# MKL28Z7 register map
Vendor: Freescale Semiconductor, Inc.; Series: Kinetis_L; File version: 1.6
CPU: CM0PLUS r0p0, little endian, no MPU, no FPU, VTOR, 2 interrupt priority bits
Registers are 32-bit, read-write, reset 0x0 unless marked. A register's access mark holds for its fields unless they carry their own. Offsets are from the block's base; [hi:lo] are bit positions; {n}, {i} and the like mark numbered series.

## USB0 — Universal Serial Bus, OTG Capable Controller
Base 0x40055000; register names take the prefix USB0_
0x00 PERID 8-bit ro reset 0x4 — Peripheral ID register
  [5:0] ID — Peripheral Identification
0x04 IDCOMP 8-bit ro reset 0xFB — Peripheral ID Complement register
  [5:0] NID — Ones' complement of PERID[ID] bits.
0x08 REV 8-bit ro reset 0x33 — Peripheral Revision register
  [7:0] REV — Revision
0x0C ADDINFO 8-bit ro reset 0x1 — Peripheral Additional Info register
  [0] IEHOST — This bit is set if host mode is enabled.
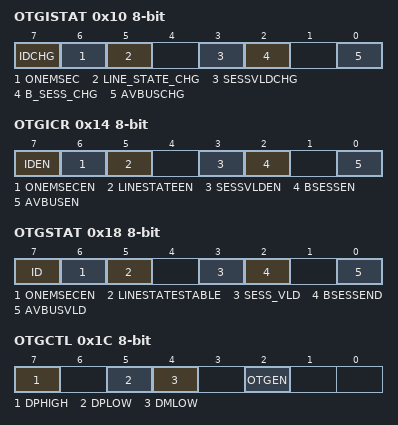
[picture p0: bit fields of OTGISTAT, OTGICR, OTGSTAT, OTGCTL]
0x10 OTGISTAT 8-bit — OTG Interrupt Status register
  [7] IDCHG — This bit is set when a change in the ID Signal from the USB connector is sensed.
  [6] ONEMSEC — This bit is set when the 1 millisecond timer expires
  [5] LINE_STATE_CHG — This interrupt is set when the USB line state (CTL[SE0] and CTL[JSTATE] bits) are stable without change for 1 millisecond, and the value of the line state is different from the last time when the line state was stable
  [3] SESSVLDCHG — This bit is set when a change in VBUS is detected indicating a session valid or a session no longer valid
  [2] B_SESS_CHG — This bit is set when a change in VBUS is detected on a B device.
  [0] AVBUSCHG — This bit is set when a change in VBUS is detected on an A device.
0x14 OTGICR 8-bit — OTG Interrupt Control register
  [7] IDEN — ID Interrupt Enable
    0=The ID interrupt is disabled; 1=The ID interrupt is enabled
  [6] ONEMSECEN — One Millisecond Interrupt Enable
    0=Diables the 1ms timer interrupt; 1=Enables the 1ms timer interrupt
  [5] LINESTATEEN — Line State Change Interrupt Enable
    0=Disables the LINE_STAT_CHG interrupt; 1=Enables the LINE_STAT_CHG interrupt
  [3] SESSVLDEN — Session Valid Interrupt Enable
    0=Disables the SESSVLDCHG interrupt; 1=Enables the SESSVLDCHG interrupt
  [2] BSESSEN — B Session END Interrupt Enable
    0=Disables the B_SESS_CHG interrupt; 1=Enables the B_SESS_CHG interrupt
  [0] AVBUSEN — A VBUS Valid Interrupt Enable
    0=Disables the AVBUSCHG interrupt; 1=Enables the AVBUSCHG interrupt
0x18 OTGSTAT 8-bit — OTG Status register
  [7] ID — Indicates the current state of the ID pin on the USB connector
    0=Indicates a Type A cable is plugged into the USB connector; 1=Indicates no cable is attached or a Type B cable is plugged into the USB connector
  [6] ONEMSECEN — This bit is reserved for the 1ms count, but it is not useful to software.
  [5] LINESTATESTABLE — Indicates that the internal signals that control the LINE_STATE_CHG field of OTGISTAT are stable for at least 1 ms
    0=The LINE_STAT_CHG bit is not yet stable; 1=The LINE_STAT_CHG bit has been debounced and is stable
  [3] SESS_VLD — Session Valid
    0=The VBUS voltage is below the B session valid threshold; 1=The VBUS voltage is above the B session valid threshold
  [2] BSESSEND — B Session End
    0=The VBUS voltage is above the B session end threshold; 1=The VBUS voltage is below the B session end threshold
  [0] AVBUSVLD — A VBUS Valid
    0=The VBUS voltage is below the A VBUS Valid threshold; 1=The VBUS voltage is above the A VBUS Valid threshold
0x1C OTGCTL 8-bit — OTG Control register
  [7] DPHIGH — D+ Data Line pullup resistor enable
    0=D+ pullup resistor is not enabled; 1=D+ pullup resistor is enabled
  [5] DPLOW — D+ Data Line pull-down resistor enable
    0=D+ pulldown resistor is not enabled; 1=D+ pulldown resistor is enabled
  [4] DMLOW — D- Data Line pull-down resistor enable
    0=D- pulldown resistor is not enabled; 1=D- pulldown resistor is enabled
  [2] OTGEN — On-The-Go pullup/pulldown resistor enable
    0=If USB_EN is 1 and HOST_MODE is 0 in the Control Register (CTL), then the D+ Data Line pull-up resistors are enabled. If HOST_MODE is 1 the D+ and D- Data Line pull-down resistors are engaged.; 1=The pull-up and pull-down controls in this register are used
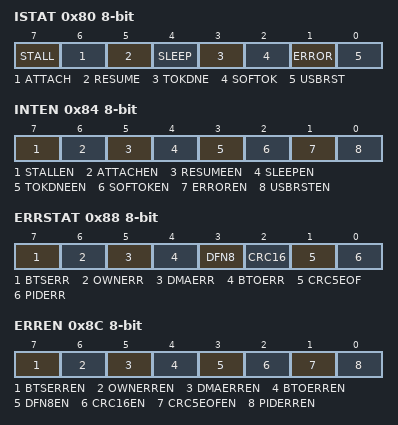
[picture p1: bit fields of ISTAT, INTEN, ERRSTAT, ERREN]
0x80 ISTAT 8-bit — Interrupt Status register
  [7] STALL — Stall Interrupt
  [6] ATTACH — Attach Interrupt
    0=No Attach is detected since the last time the ATTACH bit was cleared; 1=A peripheral is now present and must be configured (a stable non-SE0 state is detected for more than 2.5 us)
  [5] RESUME — This bit is set when a K-state is observed on the DP/DM signals for 2
  [4] SLEEP — This bit is set when the USB Module detects a constant idle on the USB bus for 3 ms
  [3] TOKDNE — This bit is set when the current token being processed has completed
  [2] SOFTOK — This bit is set when the USB Module receives a Start Of Frame (SOF) token
  [1] ERROR — This bit is set when any of the error conditions within Error Interrupt Status (ERRSTAT) register occur
  [0] USBRST — This bit is set when the USB Module has decoded a valid USB reset
0x84 INTEN 8-bit — Interrupt Enable register
  [7] STALLEN — STALL Interrupt Enable
    0=Diasbles the STALL interrupt; 1=Enables the STALL interrupt
  [6] ATTACHEN — ATTACH Interrupt Enable
    0=Disables the ATTACH interrupt; 1=Enables the ATTACH interrupt
  [5] RESUMEEN — RESUME Interrupt Enable
    0=Disables the RESUME interrupt; 1=Enables the RESUME interrupt
  [4] SLEEPEN — SLEEP Interrupt Enable
    0=Disables the SLEEP interrupt; 1=Enables the SLEEP interrupt
  [3] TOKDNEEN — TOKDNE Interrupt Enable
    0=Disables the TOKDNE interrupt; 1=Enables the TOKDNE interrupt
  [2] SOFTOKEN — SOFTOK Interrupt Enable
    0=Disbles the SOFTOK interrupt; 1=Enables the SOFTOK interrupt
  [1] ERROREN — ERROR Interrupt Enable
    0=Disables the ERROR interrupt; 1=Enables the ERROR interrupt
  [0] USBRSTEN — USBRST Interrupt Enable
    0=Disables the USBRST interrupt; 1=Enables the USBRST interrupt
0x88 ERRSTAT 8-bit — Error Interrupt Status register
  [7] BTSERR — This bit is set when a bit stuff error is detected
  [6] OWNERR — This field is valid when the USB Module is operating in peripheral mode (CTL[HOSTMODEEN]=0)
  [5] DMAERR — This bit is set if the USB Module has requested a DMA access to read a new BDT but has not been given the bus before it needs to receive or transmit data
  [4] BTOERR — This bit is set when a bus turnaround timeout error occurs
  [3] DFN8 — This bit is set if the data field received was not 8 bits in length
  [2] CRC16 — This bit is set when a data packet is rejected due to a CRC16 error.
  [1] CRC5EOF — This error interrupt has two functions
  [0] PIDERR — This bit is set when the PID check field fails.
0x8C ERREN 8-bit — Error Interrupt Enable register
  [7] BTSERREN — BTSERR Interrupt Enable
    0=Disables the BTSERR interrupt; 1=Enables the BTSERR interrupt
  [6] OWNERREN — OWNERR Interrupt Enable
    0=Disables the OWNERR interrupt; 1=Enables the OWNERR interrupt
  [5] DMAERREN — DMAERR Interrupt Enable
    0=Disables the DMAERR interrupt; 1=Enables the DMAERR interrupt
  [4] BTOERREN — BTOERR Interrupt Enable
    0=Disables the BTOERR interrupt; 1=Enables the BTOERR interrupt
  [3] DFN8EN — DFN8 Interrupt Enable
    0=Disables the DFN8 interrupt; 1=Enables the DFN8 interrupt
  [2] CRC16EN — CRC16 Interrupt Enable
    0=Disables the CRC16 interrupt; 1=Enables the CRC16 interrupt
  [1] CRC5EOFEN — CRC5/EOF Interrupt Enable
    0=Disables the CRC5/EOF interrupt; 1=Enables the CRC5/EOF interrupt
  [0] PIDERREN — PIDERR Interrupt Enable
    0=Disables the PIDERR interrupt; 1=Enters the PIDERR interrupt
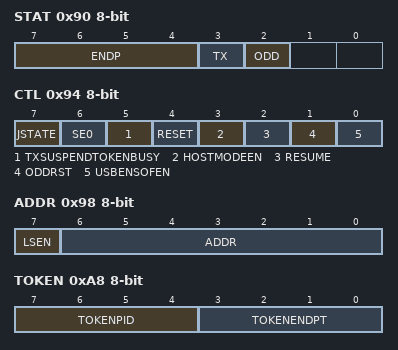
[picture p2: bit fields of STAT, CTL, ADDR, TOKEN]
0x90 STAT 8-bit ro — Status register
  [7:4] ENDP — This four-bit field encodes the endpoint address that received or transmitted the previous token
  [3] TX — Transmit Indicator
    0=The most recent transaction was a receive operation; 1=The most recent transaction was a transmit operation
  [2] ODD — This bit is set if the last buffer descriptor updated was in the odd bank of the BDT.
0x94 CTL 8-bit — Control register
  [7] JSTATE — Live USB differential receiver JSTATE signal
  [6] SE0 — Live USB Single Ended Zero signal
  [5] TXSUSPENDTOKENBUSY — In Host mode, TOKEN_BUSY is set when the USB module is busy executing a USB token
  [4] RESET — Setting this bit enables the USB Module to generate USB reset signaling
  [3] HOSTMODEEN — When set to 1, this bit enables the USB Module to operate in Host mode
  [2] RESUME — When set to 1 this bit enables the USB Module to execute resume signaling
  [1] ODDRST — Setting this bit to 1 resets all the BDT ODD ping/pong fields to 0, which then specifies the EVEN BDT bank
  [0] USBENSOFEN — USB Enable
    0=Disables the USB Module; 1=Enables the USB Module
0x98 ADDR 8-bit — Address register
  [7] LSEN — Low Speed Enable bit
  [6:0] ADDR — USB Address
0x9C BDTPAGE1 8-bit — BDT Page register 1
  [7:1] BDTBA — Provides address bits 15 through 9 of the BDT base address.
0xA0 FRMNUML 8-bit — Frame Number register Low
  [7:0] FRM — This 8-bit field and the 3-bit field in the Frame Number Register High are used to compute the address where the current Buffer Descriptor Table (BDT) resides in system memory
0xA4 FRMNUMH 8-bit — Frame Number register High
  [2:0] FRM — This 3-bit field and the 8-bit field in the Frame Number Register Low are used to compute the address where the current Buffer Descriptor Table (BDT) resides in system memory
0xA8 TOKEN 8-bit
  [7:4] TOKENPID — Contains the token type executed by the USB module.
    1=OUT Token. USB Module performs an OUT (TX) transaction.; 9=IN Token. USB Module performs an In (RX) transaction.; 13=SETUP Token. USB Module performs a SETUP (TX) transaction
  [3:0] TOKENENDPT — Holds the Endpoint address for the token command
0xAC SOFTHLD 8-bit — SOF Threshold register
  [7:0] CNT — Represents the SOF count threshold in byte times when SOFDYNTHLD=0 or 8 byte times when SOFDYNTHLD=1
0xB0 BDTPAGE2 8-bit — BDT Page Register 2
  [7:0] BDTBA — Provides address bits 23 through 16 of the BDT base address that defines the location of Buffer Descriptor Table resides in system memory
0xB4 BDTPAGE3 8-bit — BDT Page Register 3
  [7:0] BDTBA — Provides address bits 31 through 24 of the BDT base address that defines the location of Buffer Descriptor Table resides in system memory
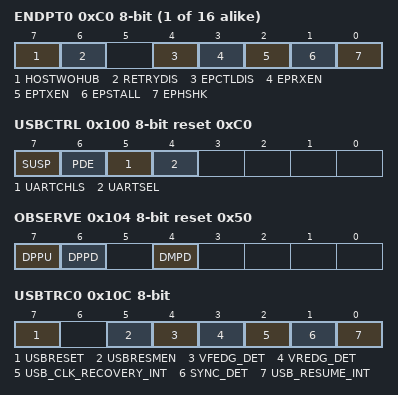
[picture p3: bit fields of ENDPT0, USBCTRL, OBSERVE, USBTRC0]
{0xC0+4i} ENDPT{i} (i=0..15) 8-bit — Endpoint Control register
  [7] HOSTWOHUB — Host without a hub This is a Host mode only field and is present in the control register for endpoint 0 (ENDPT0) only
    0=Low-speed device connected to Host through a hub. PRE_PID will be generated as required.; 1=Low-speed device directly connected. No hub, or no low-speed device attached.
  [6] RETRYDIS — This is a Host mode only bit and is present in the control register for endpoint 0 (ENDPT0) only
  [4] EPCTLDIS — This bit, when set, disables control (SETUP) transfers
  [3] EPRXEN — This bit, when set, enables the endpoint for RX transfers. See
  [2] EPTXEN — This bit, when set, enables the endpoint for TX transfers. See
  [1] EPSTALL — When set this bit indicates that the endpoint is called
  [0] EPHSHK — When set this bit enables an endpoint to perform handshaking during a transaction to this endpoint
0x100 USBCTRL 8-bit reset 0xC0 — USB Control register
  [7] SUSP — Places the USB transceiver into the suspend state.
    0=USB transceiver is not in suspend state; 1=USB transceiver is in suspend state
  [6] PDE — Enables the weak pulldowns on the USB transceiver.
    0=Weak pulldowns are disabled on D+ and D-; 1=Weak pulldowns are enabled on D+ and D-
  [5] UARTCHLS — UART Signal Channel Select
    0=USB DP/DM signals used as UART TX/RX; 1=USB DP/DM signals used as UART RX/TX
  [4] UARTSEL — Selects USB signals to be used as UART signals.
    0=USB signals not used as UART signals; 1=USB signals used as UART signals
0x104 OBSERVE 8-bit ro reset 0x50 — USB OTG Observe register
  [7] DPPU — Provides observability of the D+ Pullup enable at the USB transceiver.
    0=D+ pullup disabled; 1=D+ pullup enabled
  [6] DPPD — Provides observability of the D+ Pulldown enable at the USB transceiver.
    0=D+ pulldown disabled; 1=D+ pulldown enabled
  [4] DMPD — Provides observability of the D- Pulldown enable at the USB transceiver.
    0=D- pulldown disabled; 1=D- pulldown enabled
0x108 CONTROL 8-bit — USB OTG Control register
  [4] DPPULLUPNONOTG — Provides control of the DP Pullup in USBOTG, if USB is configured in non-OTG device mode.
    0=DP Pullup in non-OTG device mode is not enabled; 1=DP Pullup in non-OTG device mode is enabled
0x10C USBTRC0 8-bit — USB Transceiver Control register 0
  [7] USBRESET wo
    0=Normal USB module operation; 1=Returns the USB module to its reset state
  [5] USBRESMEN — Asynchronous Resume Interrupt Enable
    0=USB asynchronous wakeup from suspend mode disabled; 1=USB asynchronous wakeup from suspend mode enabled. The asynchronous resume interrupt differs from the synchronous resume interrupt in that it asynchronously detects K-state using the unfiltered state of the D+ and D- pins. This interrupt should only be enabled when the Transceiver is suspended.
  [4] VFEDG_DET — VBUS Falling Edge Interrupt Detect
    0=VBUS falling edge interrupt has not been detected; 1=VBUS falling edge interrupt has been detected
  [3] VREDG_DET — VBUS Rising Edge Interrupt Detect
    0=VBUS rising edge interrupt has not been detected; 1=VBUS rising edge interrupt has been detected
  [2] USB_CLK_RECOVERY_INT ro — Combined USB Clock Recovery interrupt status
  [1] SYNC_DET ro — Synchronous USB Interrupt Detect
    0=Synchronous interrupt has not been detected; 1=Synchronous interrupt has been detected
  [0] USB_RESUME_INT ro — USB Asynchronous Interrupt
    0=No interrupt was generated; 1=Interrupt was generated because of the USB asynchronous interrupt
0x114 USBFRMADJUST 8-bit — Frame Adjust Register
  [7:0] ADJ — Frame Adjustment
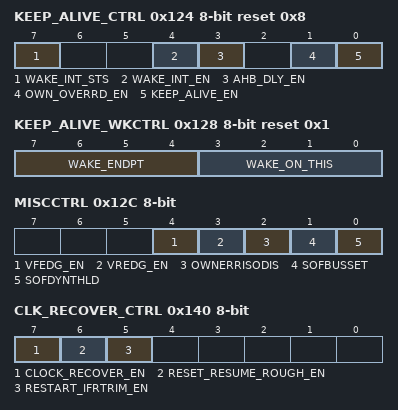
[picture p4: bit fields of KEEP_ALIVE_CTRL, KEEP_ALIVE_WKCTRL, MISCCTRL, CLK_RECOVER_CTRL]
0x124 KEEP_ALIVE_CTRL 8-bit reset 0x8 — Keep Alive mode control
  [7] WAKE_INT_STS ro — Wakeup Interrupt Status.
  [4] WAKE_INT_EN — Wakeup Interrupt Enable.
  [3] AHB_DLY_EN — Must be set to 1 to delay the first USB AHB bus transfer until after the USB has exited KEEP_ALIVE mode
    0=Do not delay the USB AHB transfer if the USB AHB transfer occurs while exiting KEEP_ALIVE mode; 1=Delay the USB AHB transfer until the clock is recovered, if the USB AHB transfer occurs while exiting KEEP_ALIVE mode
  [1] OWN_OVERRD_EN — When set to 1, during KEEP_ALIVE mode, if received token is not SETUP, the OWN bit of current BD will be forced to 0, so usb core will respond with NAK
  [0] KEEP_ALIVE_EN — Global enable for USB_KEEP_ALIVE mode
0x128 KEEP_ALIVE_WKCTRL 8-bit reset 0x1 — Keep Alive mode wakeup control
  [7:4] WAKE_ENDPT ro — Indicates which endpoint causes the wakeup interrupt. Reset to 0, software read only.
  [3:0] WAKE_ON_THIS — Software configure it to which token can wakeup usb during KEEP_ALIVE mode
    1=Wake up on receiving OUT/SETUP token packet; 13=Wake up on receiving SETUP token packet.All other values are reserved
0x12C MISCCTRL 8-bit — Miscellaneous Control register
  [4] VFEDG_EN — VBUS Falling Edge Interrupt Enable
    0=VBUS falling edge interrupt disabled; 1=VBUS falling edge interrupt enabled
  [3] VREDG_EN — VBUS Rising Edge Interrupt Enable
    0=VBUS rising edge interrupt disabled; 1=VBUS rising edge interrupt enabled
  [2] OWNERRISODIS — OWN Error Detect for ISO IN / ISO OUT Disable
    0=OWN error detect for ISO IN / ISO OUT is not disabled; 1=OWN error detect for ISO IN / ISO OUT is disabled
  [1] SOFBUSSET — SOF_TOK Interrupt Generation Mode Select
    0=SOF_TOK interrupt is set according to SOF threshold value; 1=SOF_TOK interrupt is set when SOF counter reaches 0
  [0] SOFDYNTHLD — Dynamic SOF Threshold Compare mode
    0=SOF_TOK interrupt is set when byte times SOF threshold is reached; 1=SOF_TOK interrupt is set when 8 byte times SOF threshold is reached or overstepped
0x140 CLK_RECOVER_CTRL 8-bit — USB Clock recovery control
  [7] CLOCK_RECOVER_EN — Crystal-less USB enable
    0=Disable clock recovery block (default); 1=Enable clock recovery block
  [6] RESET_RESUME_ROUGH_EN — Reset/resume to rough phase enable
    0=Always works in tracking phase after the 1st time rough to track transition (default); 1=Go back to rough stage whenever bus reset or bus resume occurs
  [5] RESTART_IFRTRIM_EN — Restart from IFR trim value
    0=Trim fine adjustment always works based on the previous updated trim fine value (default); 1=Trim fine restarts from the IFR trim value whenever bus_reset/bus_resume is detected or module enable is desasserted
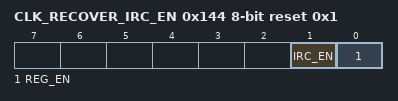
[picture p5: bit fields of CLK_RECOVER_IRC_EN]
0x144 CLK_RECOVER_IRC_EN 8-bit reset 0x1 — FIRC oscillator enable register
  [1] IRC_EN — FIRC enable This bit is used to enable the on-chip FIRC module to generate clocks for crystal-less USB
    0=Disable the FIRC module (default); 1=Enable the FIRC module
  [0] REG_EN — FIRC regulator enable This bit is used to enable the local analog regulator for FIRC module
    0=FIRC local regulator is disabled; 1=FIRC local regulator is enabled (default)
0x154 CLK_RECOVER_INT_EN 8-bit reset 0x10 — Clock recovery combined interrupt enable
  [4] OVF_ERROR_EN — Determines whether OVF_ERROR condition signal is used in generation of USB_CLK_RECOVERY_INT.
    0=The interrupt will be masked; 1=The interrupt will be enabled (default)
0x15C CLK_RECOVER_INT_STATUS 8-bit — Clock recovery separated interrupt status
  [4] OVF_ERROR — Indicates that the USB clock recovery algorithm has detected that the frequency trim adjustment needed for the FIRC output clock is outside the available TRIM_FINE adjustment range for the FIRC module
    0=No interrupt is reported; 1=Unmasked interrupt has been generated
